# nrf52805 register map
Vendor: Nordic Semiconductor; Series: nrf52; File version: 1
CPU: CM4 r0p1, little endian, MPU, no FPU, 3 interrupt priority bits
Registers are 32-bit, read-write, reset 0x0 unless marked. A register's access mark holds for its fields unless they carry their own. Offsets are from the block's base; [hi:lo] are bit positions; lines under a group give offsets from that group; {n}, {i} and the like mark numbered series; 'fields as' and 'values as' point back to an identical list.

## FICR — Factory information configuration registers
Base 0x10000000
0x10 CODEPAGESIZE ro reset 0x1000 — Code memory page size
0x14 CODESIZE ro reset 0x30 — Code memory size
  [31:0] CODESIZE — Code memory size in number of pages
{0x60+4i} DEVICEID[{i}] (i=0..1) ro reset 0xFFFFFFFF — Description collection: Device identifier
  [31:0] DEVICEID — 64 bit unique device identifier
{0x80+4i} ER[{i}] (i=0..3) ro reset 0xFFFFFFFF — Description collection: Encryption root, word n
  [31:0] ER — Encryption root, word n
{0x90+4i} IR[{i}] (i=0..3) ro reset 0xFFFFFFFF — Description collection: Identity root, word n
  [31:0] IR — Identity root, word n
0xA0 DEVICEADDRTYPE ro reset 0xFFFFFFFF — Device address type
  [0] DEVICEADDRTYPE
    0=Public address; 1=Random address
{0xA4+4i} DEVICEADDR[{i}] (i=0..1) ro reset 0xFFFFFFFF — Description collection: Device address n
  [31:0] DEVICEADDR — 48 bit device address
0x100 INFO group — Device info
  0x00 PART ro reset 0x52805 — Part code
    [31:0] PART
      0x52805=N52805 (nRF52805); 0x52810=N52810 (nRF52810); 0x52811=N52811 (nRF52811); 0x52832=N52832 (nRF52832); 0xFFFFFFFF=Unspecified
  0x04 VARIANT ro reset 0xFFFFFFFF — Part variant, hardware version and production configuration
    [31:0] VARIANT — Part variant, hardware version and production configuration, encoded as ASCII
      0x41414141=AAAA; 0x41414130=AAA0; 0x41414241=AABA; 0x41414242=AABB; 0x41414230=AAB0; 0x41414341=AACA; 0x41414342=AACB; 0x41414330=AAC0; 0xFFFFFFFF=Unspecified
  0x08 PACKAGE ro reset 0xFFFFFFFF — Package option
    [31:0] PACKAGE
      0x2004=CA (CAxx - WLCSP); 0xFFFFFFFF=Unspecified
  0x0C RAM ro reset 0x18 — RAM variant
    [31:0] RAM
      24=K24 (24 kByte RAM); 0xFFFFFFFF=Unspecified
  0x10 FLASH ro reset 0xC0 — Flash variant
    [31:0] FLASH
      192=K192 (192 kByte flash); 0xFFFFFFFF=Unspecified
0x404 TEMP group — Registers storing factory TEMP module linearization coefficients
  {0x0+4j} A{j} ro reset 0xFFFFFFFF (j=0..5) — Slope definition A{j}
    [11:0] A — A (slope definition) register
  {0x18+4j} B{j} ro reset 0xFFFFFFFF (j=0..5) — Y-intercept B{j}
    [13:0] B — B (y-intercept)
  {0x30+4j} T{j} ro reset 0xFFFFFFFF (j=0..4) — Segment end T{j}
    [7:0] T — T (segment end) register

## UICR — User information configuration registers
Base 0x10001000
{0x14+4i} NRFFW[{i}] (i=0..12) reset 0xFFFFFFFF — Description collection: Reserved for Nordic firmware design
  [31:0] NRFFW — Reserved for Nordic firmware design
{0x50+4i} NRFHW[{i}] (i=0..11) reset 0xFFFFFFFF — Description collection: Reserved for Nordic hardware design
  [31:0] NRFHW — Reserved for Nordic hardware design
{0x80+4i} CUSTOMER[{i}] (i=0..31) reset 0xFFFFFFFF — Description collection: Reserved for customer
  [31:0] CUSTOMER — Reserved for customer
{0x100+4i} NRFMDK[{i}] (i=0..7) reset 0xFFFFFFFF — Description collection: Reserved for Nordic MDK
  [31:0] NRFMDK — Reserved for Nordic MDK
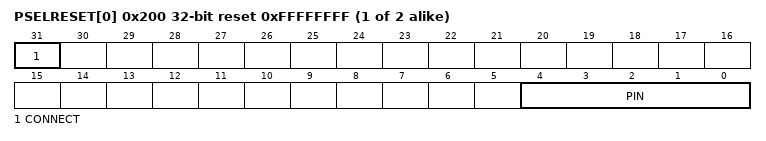
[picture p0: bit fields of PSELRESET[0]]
{0x200+4i} PSELRESET[{i}] (i=0..1) reset 0xFFFFFFFF — Description collection: Mapping of the nRESET function (see POWER chapter for details)
  [31] CONNECT — Connection
    1=Disconnected; 0=Connected
  [4:0] PIN — GPIO pin number onto which nRESET is exposed
0x208 APPROTECT reset 0xFFFFFFFF — Access port protection
  [7:0] PALL — Enable or disable access port protection.
    255=Disabled (Hardware disable of access port protection for devices where access port protection is controlled by hardware); 90=HwDisabled (Hardware disable of access port protection for devices where access port protection is controlled by hardware and software); 0=Enabled

## BPROT — Block Protect
Base 0x40000000
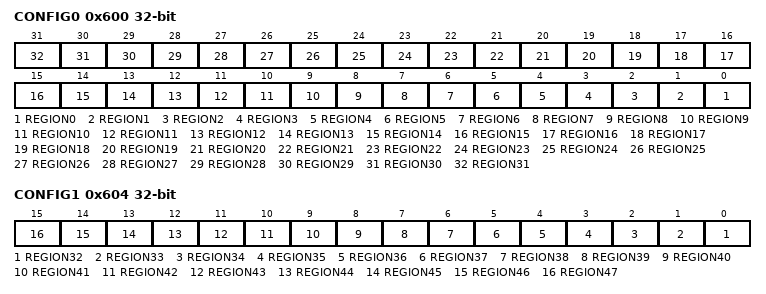
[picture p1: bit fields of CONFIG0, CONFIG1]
0x600 CONFIG0 — Block protect configuration register 0
  [all] fields
    0=Disabled (Protection disabled); 1=Enabled (Protection enabled)
  [n] REGION{n} (n=0..31) — Enable protection for region {n}. Write '0' has no effect.
0x604 CONFIG1 — Block protect configuration register 1
  [all] fields
    values as the fields of CONFIG0
  [n-32] REGION{n} (n=32..47) — Enable protection for region {n}. Write '0' has no effect.
0x608 DISABLEINDEBUG reset 0x1 — Disable protection mechanism in debug mode
  [0] DISABLEINDEBUG — Disable the protection mechanism for NVM regions while in debug mode. This register will only disable the protection mechanism if the device is in debug mode.
    1=Disabled in debug; 0=Enabled in debug

## Notices in the file
Copyright (c) 2010 - 2023, Nordic Semiconductor ASA
All rights reserved.
Redistribution and use in source and binary forms, with or without modification,
are permitted provided that the following conditions are met:
1. Redistributions of source code must retain the above copyright notice, this
list of conditions and the following disclaimer.
2. Redistributions in binary form, except as embedded into a Nordic
Semiconductor ASA integrated circuit in a product or a software update for
such product, must reproduce the above copyright notice, this list of
conditions and the following disclaimer in the documentation and/or other
materials provided with the distribution.
3. Neither the name of Nordic Semiconductor ASA nor the names of its
contributors may be used to endorse or promote products derived from this
software without specific prior written permission.
4. This software, with or without modification, must only be used with a
Nordic Semiconductor ASA integrated circuit.
5. Any software provided in binary form under this license must not be reverse
engineered, decompiled, modified and/or disassembled.
THIS SOFTWARE IS PROVIDED BY NORDIC SEMICONDUCTOR ASA "AS IS" AND ANY EXPRESS
OR IMPLIED WARRANTIES, INCLUDING, BUT NOT LIMITED TO, THE IMPLIED WARRANTIES
OF MERCHANTABILITY, NONINFRINGEMENT, AND FITNESS FOR A PARTICULAR PURPOSE ARE
DISCLAIMED. IN NO EVENT SHALL NORDIC SEMICONDUCTOR ASA OR CONTRIBUTORS BE
LIABLE FOR ANY DIRECT, INDIRECT, INCIDENTAL, SPECIAL, EXEMPLARY, OR
CONSEQUENTIAL DAMAGES (INCLUDING, BUT NOT LIMITED TO, PROCUREMENT OF SUBSTITUTE
GOODS OR SERVICES; LOSS OF USE, DATA, OR PROFITS; OR BUSINESS INTERRUPTION)
HOWEVER CAUSED AND ON ANY THEORY OF LIABILITY, WHETHER IN CONTRACT, STRICT
LIABILITY, OR TORT (INCLUDING NEGLIGENCE OR OTHERWISE) ARISING IN ANY WAY OUT
OF THE USE OF THIS SOFTWARE, EVEN IF ADVISED OF THE POSSIBILITY OF SUCH DAMAGE.
